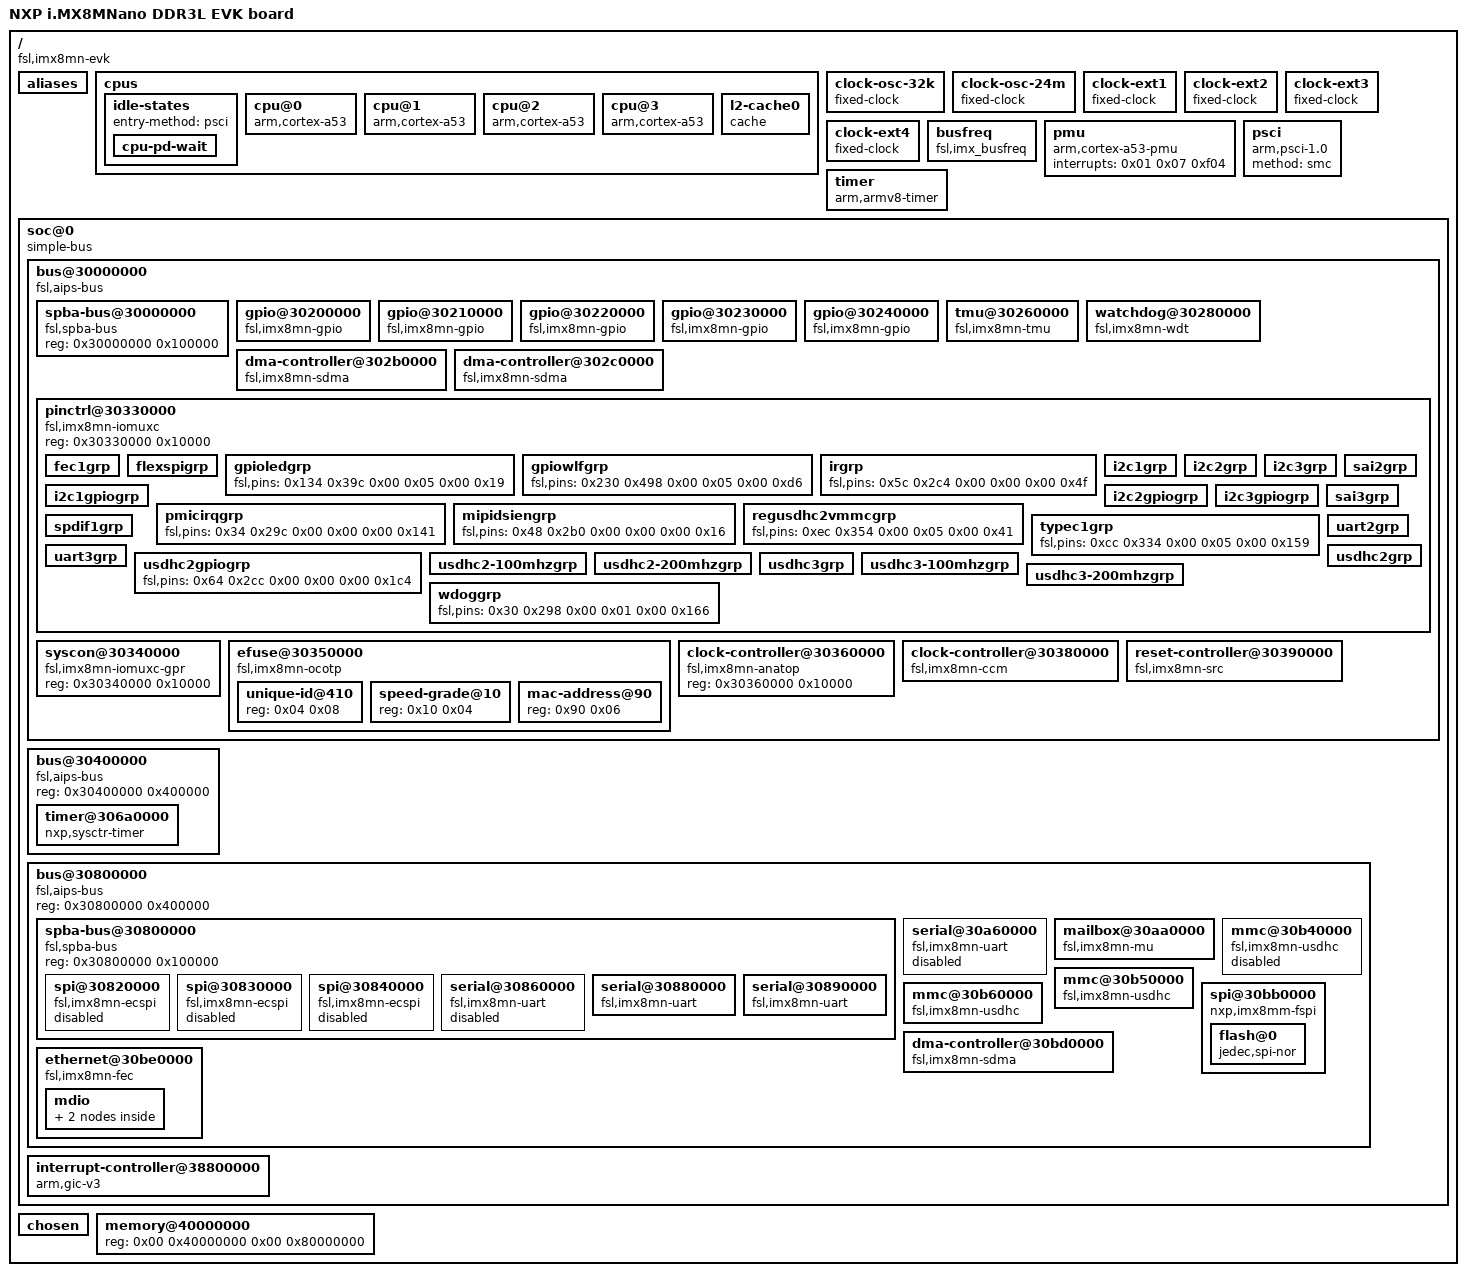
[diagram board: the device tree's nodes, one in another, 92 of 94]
/dts-v1/;

/ {
	interrupt-parent = <0x01>;
	#address-cells = <0x02>;
	#size-cells = <0x02>;
	model = "NXP i.MX8MNano DDR3L EVK board";
	compatible = "fsl,imx8mn-evk\0fsl,imx8mn";

	aliases {
		ethernet0 = "/soc@0/bus@30800000/ethernet@30be0000";
		gpio0 = "/soc@0/bus@30000000/gpio@30200000";
		gpio1 = "/soc@0/bus@30000000/gpio@30210000";
		gpio2 = "/soc@0/bus@30000000/gpio@30220000";
		gpio3 = "/soc@0/bus@30000000/gpio@30230000";
		gpio4 = "/soc@0/bus@30000000/gpio@30240000";
		mmc0 = "/soc@0/bus@30800000/mmc@30b40000";
		mmc1 = "/soc@0/bus@30800000/mmc@30b50000";
		mmc2 = "/soc@0/bus@30800000/mmc@30b60000";
		serial0 = "/soc@0/bus@30800000/spba-bus@30800000/serial@30860000";
		serial1 = "/soc@0/bus@30800000/spba-bus@30800000/serial@30890000";
		serial2 = "/soc@0/bus@30800000/spba-bus@30800000/serial@30880000";
		serial3 = "/soc@0/bus@30800000/serial@30a60000";
		spi0 = "/soc@0/bus@30800000/spi@30bb0000";
	};

	cpus {
		#address-cells = <0x01>;
		#size-cells = <0x00>;

		idle-states {
			entry-method = "psci";

			cpu-pd-wait {
				arm,psci-suspend-param = <0x10033>;
				local-timer-stop;
				entry-latency-us = <0x3e8>;
				exit-latency-us = <0x2bc>;
				min-residency-us = <0xa8c>;
				phandle = <0x06>;
			};
		};

		cpu@0 {
			device_type = "cpu";
			compatible = "arm,cortex-a53";
			reg = <0x00>;
			clock-latency = <0xee6c>;
			clocks = <0x02 0xbf>;
			enable-method = "psci";
			i-cache-size = <0x8000>;
			i-cache-line-size = <0x40>;
			i-cache-sets = <0x100>;
			d-cache-size = <0x8000>;
			d-cache-line-size = <0x40>;
			d-cache-sets = <0x80>;
			next-level-cache = <0x03>;
			operating-points-v2 = <0x04>;
			nvmem-cells = <0x05>;
			nvmem-cell-names = "speed_grade";
			cpu-idle-states = <0x06>;
			#cooling-cells = <0x02>;
			cpu-supply = <0x07>;
			phandle = <0x0a>;
		};

		cpu@1 {
			device_type = "cpu";
			compatible = "arm,cortex-a53";
			reg = <0x01>;
			clock-latency = <0xee6c>;
			clocks = <0x02 0xbf>;
			enable-method = "psci";
			i-cache-size = <0x8000>;
			i-cache-line-size = <0x40>;
			i-cache-sets = <0x100>;
			d-cache-size = <0x8000>;
			d-cache-line-size = <0x40>;
			d-cache-sets = <0x80>;
			next-level-cache = <0x03>;
			operating-points-v2 = <0x04>;
			cpu-idle-states = <0x06>;
			#cooling-cells = <0x02>;
			cpu-supply = <0x07>;
			phandle = <0x0b>;
		};

		cpu@2 {
			device_type = "cpu";
			compatible = "arm,cortex-a53";
			reg = <0x02>;
			clock-latency = <0xee6c>;
			clocks = <0x02 0xbf>;
			enable-method = "psci";
			i-cache-size = <0x8000>;
			i-cache-line-size = <0x40>;
			i-cache-sets = <0x100>;
			d-cache-size = <0x8000>;
			d-cache-line-size = <0x40>;
			d-cache-sets = <0x80>;
			next-level-cache = <0x03>;
			operating-points-v2 = <0x04>;
			cpu-idle-states = <0x06>;
			#cooling-cells = <0x02>;
			cpu-supply = <0x07>;
			phandle = <0x0c>;
		};

		cpu@3 {
			device_type = "cpu";
			compatible = "arm,cortex-a53";
			reg = <0x03>;
			clock-latency = <0xee6c>;
			clocks = <0x02 0xbf>;
			enable-method = "psci";
			i-cache-size = <0x8000>;
			i-cache-line-size = <0x40>;
			i-cache-sets = <0x100>;
			d-cache-size = <0x8000>;
			d-cache-line-size = <0x40>;
			d-cache-sets = <0x80>;
			next-level-cache = <0x03>;
			operating-points-v2 = <0x04>;
			cpu-idle-states = <0x06>;
			#cooling-cells = <0x02>;
			cpu-supply = <0x07>;
			phandle = <0x0d>;
		};

		l2-cache0 {
			compatible = "cache";
			cache-level = <0x02>;
			cache-size = <0x80000>;
			cache-line-size = <0x40>;
			cache-sets = <0x200>;
			phandle = <0x03>;
		};
	};

	clock-osc-32k {
		compatible = "fixed-clock";
		#clock-cells = <0x00>;
		clock-frequency = <0x8000>;
		clock-output-names = "osc_32k";
		u-boot,dm-spl;
		u-boot,dm-pre-reloc;
		phandle = <0x16>;
	};

	clock-osc-24m {
		compatible = "fixed-clock";
		#clock-cells = <0x00>;
		clock-frequency = <0x16e3600>;
		clock-output-names = "osc_24m";
		u-boot,dm-spl;
		u-boot,dm-pre-reloc;
		phandle = <0x17>;
	};

	clock-ext1 {
		compatible = "fixed-clock";
		#clock-cells = <0x00>;
		clock-frequency = <0x7ed6b40>;
		clock-output-names = "clk_ext1";
		u-boot,dm-spl;
		u-boot,dm-pre-reloc;
		phandle = <0x18>;
	};

	clock-ext2 {
		compatible = "fixed-clock";
		#clock-cells = <0x00>;
		clock-frequency = <0x7ed6b40>;
		clock-output-names = "clk_ext2";
		u-boot,dm-spl;
		u-boot,dm-pre-reloc;
		phandle = <0x19>;
	};

	clock-ext3 {
		compatible = "fixed-clock";
		#clock-cells = <0x00>;
		clock-frequency = <0x7ed6b40>;
		clock-output-names = "clk_ext3";
		u-boot,dm-spl;
		u-boot,dm-pre-reloc;
		phandle = <0x1a>;
	};

	clock-ext4 {
		compatible = "fixed-clock";
		#clock-cells = <0x00>;
		clock-frequency = <0x7ed6b40>;
		clock-output-names = "clk_ext4";
		u-boot,dm-spl;
		u-boot,dm-pre-reloc;
		phandle = <0x1b>;
	};

	busfreq {
		compatible = "fsl,imx_busfreq";
		clocks = <0x02 0x29 0x02 0x59 0x02 0x5a 0x02 0x5a 0x02 0x58 0x02 0x5b 0x02 0x30 0x02 0x32 0x02 0x3f 0x02 0x53 0x02 0x54 0x02 0x4b 0x02 0x02 0x02 0x38 0x02 0x15>;
		clock-names = "dram_pll\0dram_alt_src\0dram_apb_src\0dram_apb_pre_div\0dram_core\0dram_alt_root\0sys_pll1_40m\0sys_pll1_100m\0sys_pll2_333m\0noc_div\0ahb_div\0main_axi_src\0osc_24m\0sys_pll1_800m\0dram_pll_div";
	};

	pmu {
		compatible = "arm,cortex-a53-pmu";
		interrupts = <0x01 0x07 0xf04>;
	};

	psci {
		compatible = "arm,psci-1.0";
		method = "smc";
	};

	timer {
		compatible = "arm,armv8-timer";
		interrupts = <0x01 0x0d 0xf08 0x01 0x0e 0xf08 0x01 0x0b 0xf08 0x01 0x0a 0xf08>;
		clock-frequency = <0x7a1200>;
		arm,no-tick-in-suspend;
	};

	soc@0 {
		compatible = "simple-bus";
		#address-cells = <0x01>;
		#size-cells = <0x01>;
		ranges = <0x00 0x00 0x00 0x3e000000>;
		dma-ranges = <0x40000000 0x00 0x40000000 0xc0000000>;
		nvmem-cells = <0x0e>;
		nvmem-cell-names = "soc_unique_id";
		u-boot,dm-pre-reloc;
		u-boot,dm-spl;
		phandle = <0x5e>;

		bus@30000000 {
			compatible = "fsl,aips-bus\0simple-bus";
			reg = <0x30000000 0x400000>;
			#address-cells = <0x01>;
			#size-cells = <0x01>;
			ranges;
			u-boot,dm-spl;
			u-boot,dm-pre-reloc;
			phandle = <0x60>;

			spba-bus@30000000 {
				compatible = "fsl,spba-bus\0simple-bus";
				#address-cells = <0x01>;
				#size-cells = <0x01>;
				reg = <0x30000000 0x100000>;
				ranges;
				phandle = <0x61>;

			};

			gpio@30200000 {
				compatible = "fsl,imx8mn-gpio\0fsl,imx35-gpio";
				reg = <0x30200000 0x10000>;
				interrupts = <0x00 0x40 0x04 0x00 0x41 0x04>;
				clocks = <0x02 0x8c>;
				gpio-controller;
				#gpio-cells = <0x02>;
				interrupt-controller;
				#interrupt-cells = <0x02>;
				gpio-ranges = <0x13 0x00 0x0a 0x1e>;
				u-boot,dm-spl;
				phandle = <0x24>;
			};

			gpio@30210000 {
				compatible = "fsl,imx8mn-gpio\0fsl,imx35-gpio";
				reg = <0x30210000 0x10000>;
				interrupts = <0x00 0x42 0x04 0x00 0x43 0x04>;
				clocks = <0x02 0x8d>;
				gpio-controller;
				#gpio-cells = <0x02>;
				interrupt-controller;
				#interrupt-cells = <0x02>;
				gpio-ranges = <0x13 0x00 0x28 0x15>;
				u-boot,dm-spl;
				phandle = <0x29>;
			};

			gpio@30220000 {
				compatible = "fsl,imx8mn-gpio\0fsl,imx35-gpio";
				reg = <0x30220000 0x10000>;
				interrupts = <0x00 0x44 0x04 0x00 0x45 0x04>;
				clocks = <0x02 0x8e>;
				gpio-controller;
				#gpio-cells = <0x02>;
				interrupt-controller;
				#interrupt-cells = <0x02>;
				gpio-ranges = <0x13 0x00 0x3d 0x1a>;
				u-boot,dm-spl;
				phandle = <0x4d>;
			};

			gpio@30230000 {
				compatible = "fsl,imx8mn-gpio\0fsl,imx35-gpio";
				reg = <0x30230000 0x10000>;
				interrupts = <0x00 0x46 0x04 0x00 0x47 0x04>;
				clocks = <0x02 0x8f>;
				gpio-controller;
				#gpio-cells = <0x02>;
				interrupt-controller;
				#interrupt-cells = <0x02>;
				gpio-ranges = <0x13 0x15 0x6c 0x0b>;
				u-boot,dm-spl;
				phandle = <0x3a>;
			};

			gpio@30240000 {
				compatible = "fsl,imx8mn-gpio\0fsl,imx35-gpio";
				reg = <0x30240000 0x10000>;
				interrupts = <0x00 0x48 0x04 0x00 0x49 0x04>;
				clocks = <0x02 0x90>;
				gpio-controller;
				#gpio-cells = <0x02>;
				interrupt-controller;
				#interrupt-cells = <0x02>;
				gpio-ranges = <0x13 0x00 0x77 0x1e>;
				u-boot,dm-spl;
				phandle = <0x22>;
			};

			tmu@30260000 {
				compatible = "fsl,imx8mn-tmu\0fsl,imx8mm-tmu";
				reg = <0x30260000 0x10000>;
				clocks = <0x02 0xbe>;
				#thermal-sensor-cells = <0x00>;
				u-boot,dm-pre-reloc;
				phandle = <0x08>;
			};

			watchdog@30280000 {
				compatible = "fsl,imx8mn-wdt\0fsl,imx21-wdt";
				reg = <0x30280000 0x10000>;
				interrupts = <0x00 0x4e 0x04>;
				clocks = <0x02 0xb0>;
				status = "okay";
				pinctrl-names = "default";
				pinctrl-0 = <0x14>;
				fsl,ext-reset-output;
				u-boot,dm-spl;
				phandle = <0x5a>;
			};


			dma-controller@302b0000 {
				compatible = "fsl,imx8mn-sdma\0fsl,imx8mq-sdma";
				reg = <0x302b0000 0x10000>;
				interrupts = <0x00 0x22 0x04>;
				clocks = <0x02 0xbd 0x02 0xbd>;
				clock-names = "ipg\0ahb";
				#dma-cells = <0x03>;
				fsl,sdma-ram-script-name = "imx/sdma/sdma-imx7d.bin";
				phandle = <0x68>;
			};

			dma-controller@302c0000 {
				compatible = "fsl,imx8mn-sdma\0fsl,imx8mq-sdma";
				reg = <0x302c0000 0x10000>;
				interrupts = <0x00 0x67 0x04>;
				clocks = <0x02 0xa8 0x02 0xa8>;
				clock-names = "ipg\0ahb";
				#dma-cells = <0x03>;
				fsl,sdma-ram-script-name = "imx/sdma/sdma-imx7d.bin";
				phandle = <0x0f>;
			};

			pinctrl@30330000 {
				compatible = "fsl,imx8mn-iomuxc";
				reg = <0x30330000 0x10000>;
				u-boot,dm-spl;
				phandle = <0x13>;

				fec1grp {
					fsl,pins = <0x68 0x2d0 0x00 0x00 0x00 0x03 0x6c 0x2d4 0x4c0 0x00 0x01 0x03 0x70 0x2d8 0x00 0x00 0x00 0x1f 0x74 0x2dc 0x00 0x00 0x00 0x1f 0x78 0x2e0 0x00 0x00 0x00 0x1f 0x7c 0x2e4 0x00 0x00 0x00 0x1f 0x9c 0x304 0x00 0x00 0x00 0x91 0x98 0x300 0x00 0x00 0x00 0x91 0x94 0x2fc 0x554 0x00 0x00 0x91 0x90 0x2f8 0x57c 0x00 0x00 0x91 0x84 0x2ec 0x00 0x00 0x00 0x1f 0x8c 0x2f4 0x00 0x00 0x00 0x91 0x88 0x2f0 0x574 0x00 0x00 0x91 0x80 0x2e8 0x00 0x00 0x00 0x1f 0x1b4 0x41c 0x00 0x05 0x00 0x19>;
					phandle = <0x38>;
				};

				flexspigrp {
					fsl,pins = <0xf4 0x35c 0x00 0x01 0x00 0x1c2 0xf8 0x360 0x00 0x01 0x00 0x82 0x10c 0x374 0x00 0x01 0x00 0x82 0x110 0x378 0x00 0x01 0x00 0x82 0x114 0x37c 0x00 0x01 0x00 0x82 0x118 0x380 0x00 0x01 0x00 0x82>;
					phandle = <0x35>;
				};

				gpioledgrp {
					fsl,pins = <0x134 0x39c 0x00 0x05 0x00 0x19>;
					phandle = <0x4c>;
				};

				gpiowlfgrp {
					fsl,pins = <0x230 0x498 0x00 0x05 0x00 0xd6>;
					phandle = <0x50>;
				};

				irgrp {
					fsl,pins = <0x5c 0x2c4 0x00 0x00 0x00 0x4f>;
					phandle = <0x4f>;
				};

				i2c1grp {
					fsl,pins = <0x214 0x47c 0x55c 0x00 0x00 0x400001c3 0x218 0x480 0x56c 0x00 0x00 0x400001c3>;
					u-boot,dm-spl;
					phandle = <0x20>;
				};

				i2c2grp {
					fsl,pins = <0x21c 0x484 0x5d0 0x00 0x00 0x400001c3 0x220 0x488 0x560 0x00 0x00 0x400001c3>;
					phandle = <0x25>;
				};

				i2c3grp {
					fsl,pins = <0x224 0x48c 0x588 0x00 0x00 0x400001c3 0x228 0x490 0x5bc 0x00 0x00 0x400001c3>;
					phandle = <0x2b>;
				};

				i2c1gpiogrp {
					fsl,pins = <0x214 0x47c 0x00 0x05 0x00 0x1c3 0x218 0x480 0x00 0x05 0x00 0x1c3>;
					u-boot,dm-spl;
					phandle = <0x21>;
				};

				i2c2gpiogrp {
					fsl,pins = <0x21c 0x484 0x00 0x05 0x00 0x1c3 0x220 0x488 0x00 0x05 0x00 0x1c3>;
					phandle = <0x26>;
				};

				i2c3gpiogrp {
					fsl,pins = <0x224 0x48c 0x00 0x05 0x00 0x1c3 0x228 0x490 0x00 0x05 0x00 0x1c3>;
					phandle = <0x2c>;
				};

				pmicirqgrp {
					fsl,pins = <0x34 0x29c 0x00 0x00 0x00 0x141>;
					u-boot,dm-spl;
					phandle = <0x23>;
				};

				mipidsiengrp {
					fsl,pins = <0x48 0x2b0 0x00 0x00 0x00 0x16>;
					phandle = <0x58>;
				};

				regusdhc2vmmcgrp {
					fsl,pins = <0xec 0x354 0x00 0x05 0x00 0x41>;
					u-boot,dm-spl;
					phandle = <0x4e>;
				};

				sai2grp {
					fsl,pins = <0x1c0 0x428 0x00 0x00 0x00 0xd6 0x1bc 0x424 0x00 0x00 0x00 0xd6 0x1c4 0x42c 0x00 0x00 0x00 0xd6 0x1b8 0x420 0x00 0x00 0x00 0xd6>;
					phandle = <0x10>;
				};

				sai3grp {
					fsl,pins = <0x1d8 0x440 0x00 0x00 0x00 0xd6 0x1dc 0x444 0x00 0x00 0x00 0xd6 0x1e4 0x44c 0x5c0 0x00 0x00 0xd6 0x1e0 0x448 0x00 0x00 0x00 0xd6>;
					phandle = <0x11>;
				};

				spdif1grp {
					fsl,pins = <0x1e8 0x450 0x00 0x00 0x00 0xd6 0x1ec 0x454 0x5cc 0x00 0x00 0xd6>;
					phandle = <0x12>;
				};

				typec1grp {
					fsl,pins = <0xcc 0x334 0x00 0x05 0x00 0x159>;
					phandle = <0x28>;
				};

				uart2grp {
					fsl,pins = <0x23c 0x4a4 0x4fc 0x00 0x00 0x140 0x240 0x4a8 0x00 0x00 0x00 0x140>;
					u-boot,dm-spl;
					phandle = <0x1f>;
				};

				uart3grp {
					fsl,pins = <0x1f4 0x45c 0x504 0x01 0x00 0x140 0x1f8 0x460 0x00 0x01 0x00 0x140 0x200 0x468 0x500 0x01 0x01 0x140 0x1fc 0x464 0x00 0x01 0x00 0x140>;
					phandle = <0x1e>;
				};

				usdhc2gpiogrp {
					fsl,pins = <0x64 0x2cc 0x00 0x00 0x00 0x1c4>;
					u-boot,dm-spl;
					phandle = <0x2e>;
				};

				usdhc2grp {
					fsl,pins = <0xd4 0x33c 0x00 0x00 0x00 0x190 0xd8 0x340 0x00 0x00 0x00 0x1d0 0xdc 0x344 0x00 0x00 0x00 0x1d0 0xe0 0x348 0x00 0x00 0x00 0x1d0 0xe4 0x34c 0x00 0x00 0x00 0x1d0 0xe8 0x350 0x00 0x00 0x00 0x1d0 0x38 0x2a0 0x00 0x01 0x00 0x1d0>;
					u-boot,dm-spl;
					phandle = <0x2d>;
				};

				usdhc2-100mhzgrp {
					fsl,pins = <0xd4 0x33c 0x00 0x00 0x00 0x194 0xd8 0x340 0x00 0x00 0x00 0x1d4 0xdc 0x344 0x00 0x00 0x00 0x1d4 0xe0 0x348 0x00 0x00 0x00 0x1d4 0xe4 0x34c 0x00 0x00 0x00 0x1d4 0xe8 0x350 0x00 0x00 0x00 0x1d4 0x38 0x2a0 0x00 0x01 0x00 0x1d0>;
					phandle = <0x2f>;
				};

				usdhc2-200mhzgrp {
					fsl,pins = <0xd4 0x33c 0x00 0x00 0x00 0x196 0xd8 0x340 0x00 0x00 0x00 0x1d6 0xdc 0x344 0x00 0x00 0x00 0x1d6 0xe0 0x348 0x00 0x00 0x00 0x1d6 0xe4 0x34c 0x00 0x00 0x00 0x1d6 0xe8 0x350 0x00 0x00 0x00 0x1d6 0x38 0x2a0 0x00 0x01 0x00 0x1d0>;
					phandle = <0x30>;
				};

				usdhc3grp {
					fsl,pins = <0x138 0x3a0 0x5a0 0x02 0x00 0x40000190 0x13c 0x3a4 0x5dc 0x02 0x00 0x1d0 0x11c 0x384 0x5b4 0x02 0x00 0x1d0 0x120 0x388 0x5b0 0x02 0x00 0x1d0 0x124 0x38c 0x5e4 0x02 0x00 0x1d0 0x128 0x390 0x5e0 0x02 0x00 0x1d0 0x130 0x398 0x558 0x02 0x00 0x1d0 0x100 0x368 0x550 0x02 0x00 0x1d0 0x104 0x36c 0x584 0x02 0x00 0x1d0 0x108 0x370 0x54c 0x02 0x00 0x1d0 0xfc 0x364 0x59c 0x02 0x00 0x190>;
					u-boot,dm-spl;
					phandle = <0x32>;
				};

				usdhc3-100mhzgrp {
					fsl,pins = <0x138 0x3a0 0x5a0 0x02 0x00 0x40000194 0x13c 0x3a4 0x5dc 0x02 0x00 0x1d4 0x11c 0x384 0x5b4 0x02 0x00 0x1d4 0x120 0x388 0x5b0 0x02 0x00 0x1d4 0x124 0x38c 0x5e4 0x02 0x00 0x1d4 0x128 0x390 0x5e0 0x02 0x00 0x1d4 0x130 0x398 0x558 0x02 0x00 0x1d4 0x100 0x368 0x550 0x02 0x00 0x1d4 0x104 0x36c 0x584 0x02 0x00 0x1d4 0x108 0x370 0x54c 0x02 0x00 0x1d4 0xfc 0x364 0x59c 0x02 0x00 0x194>;
					phandle = <0x33>;
				};

				usdhc3-200mhzgrp {
					fsl,pins = <0x138 0x3a0 0x5a0 0x02 0x00 0x40000196 0x13c 0x3a4 0x5dc 0x02 0x00 0x1d6 0x11c 0x384 0x5b4 0x02 0x00 0x1d6 0x120 0x388 0x5b0 0x02 0x00 0x1d6 0x124 0x38c 0x5e4 0x02 0x00 0x1d6 0x128 0x390 0x5e0 0x02 0x00 0x1d6 0x130 0x398 0x558 0x02 0x00 0x1d6 0x100 0x368 0x550 0x02 0x00 0x1d6 0x104 0x36c 0x584 0x02 0x00 0x1d6 0x108 0x370 0x54c 0x02 0x00 0x1d6 0xfc 0x364 0x59c 0x02 0x00 0x196>;
					phandle = <0x34>;
				};

				wdoggrp {
					fsl,pins = <0x30 0x298 0x00 0x01 0x00 0x166>;
					u-boot,dm-spl;
					phandle = <0x14>;
				};
			};

			syscon@30340000 {
				compatible = "fsl,imx8mn-iomuxc-gpr\0syscon";
				reg = <0x30340000 0x10000>;
				phandle = <0x37>;
			};

			efuse@30350000 {
				compatible = "fsl,imx8mn-ocotp\0fsl,imx8mm-ocotp\0syscon";
				reg = <0x30350000 0x10000>;
				clocks = <0x02 0x96>;
				#address-cells = <0x01>;
				#size-cells = <0x01>;
				phandle = <0x69>;

				unique-id@410 {
					reg = <0x04 0x08>;
					phandle = <0x0e>;
				};

				speed-grade@10 {
					reg = <0x10 0x04>;
					phandle = <0x05>;
				};

				mac-address@90 {
					reg = <0x90 0x06>;
					phandle = <0x36>;
				};
			};

			clock-controller@30360000 {
				compatible = "fsl,imx8mn-anatop\0fsl,imx8mm-anatop";
				reg = <0x30360000 0x10000>;
				#clock-cells = <0x01>;
				phandle = <0x6a>;
			};

			clock-controller@30380000 {
				compatible = "fsl,imx8mn-ccm";
				reg = <0x30380000 0x10000>;
				#clock-cells = <0x01>;
				clocks = <0x16 0x17 0x18 0x19 0x1a 0x1b>;
				clock-names = "osc_32k\0osc_24m\0clk_ext1\0clk_ext2\0clk_ext3\0clk_ext4";
				u-boot,dm-spl;
				u-boot,dm-pre-reloc;
				phandle = <0x02>;
			};

			reset-controller@30390000 {
				compatible = "fsl,imx8mn-src\0fsl,imx8mq-src\0syscon";
				reg = <0x30390000 0x10000>;
				interrupts = <0x00 0x59 0x04>;
				#reset-cells = <0x01>;
				phandle = <0x6f>;
			};

		};

		bus@30400000 {
			compatible = "fsl,aips-bus\0simple-bus";
			reg = <0x30400000 0x400000>;
			#address-cells = <0x01>;
			#size-cells = <0x01>;
			ranges;
			u-boot,dm-spl;
			phandle = <0x71>;

			timer@306a0000 {
				compatible = "nxp,sysctr-timer";
				reg = <0x306a0000 0x20000>;
				interrupts = <0x00 0x2f 0x04>;
				clocks = <0x17>;
				clock-names = "per";
				phandle = <0x76>;
			};
		};

		bus@30800000 {
			compatible = "fsl,aips-bus\0simple-bus";
			reg = <0x30800000 0x400000>;
			#address-cells = <0x01>;
			#size-cells = <0x01>;
			ranges;
			u-boot,dm-spl;
			phandle = <0x77>;

			spba-bus@30800000 {
				compatible = "fsl,spba-bus\0simple-bus";
				#address-cells = <0x01>;
				#size-cells = <0x01>;
				reg = <0x30800000 0x100000>;
				ranges;
				u-boot,dm-spl;
				phandle = <0x78>;

				spi@30820000 {
					compatible = "fsl,imx8mn-ecspi\0fsl,imx51-ecspi";
					#address-cells = <0x01>;
					#size-cells = <0x00>;
					reg = <0x30820000 0x10000>;
					interrupts = <0x00 0x1f 0x04>;
					clocks = <0x02 0x88 0x02 0x88>;
					clock-names = "ipg\0per";
					dmas = <0x1d 0x00 0x07 0x01 0x1d 0x01 0x07 0x02>;
					dma-names = "rx\0tx";
					status = "disabled";
					phandle = <0x79>;
				};

				spi@30830000 {
					compatible = "fsl,imx8mn-ecspi\0fsl,imx51-ecspi";
					#address-cells = <0x01>;
					#size-cells = <0x00>;
					reg = <0x30830000 0x10000>;
					interrupts = <0x00 0x20 0x04>;
					clocks = <0x02 0x89 0x02 0x89>;
					clock-names = "ipg\0per";
					dmas = <0x1d 0x02 0x07 0x01 0x1d 0x03 0x07 0x02>;
					dma-names = "rx\0tx";
					status = "disabled";
					phandle = <0x7a>;
				};

				spi@30840000 {
					compatible = "fsl,imx8mn-ecspi\0fsl,imx51-ecspi";
					#address-cells = <0x01>;
					#size-cells = <0x00>;
					reg = <0x30840000 0x10000>;
					interrupts = <0x00 0x21 0x04>;
					clocks = <0x02 0x8a 0x02 0x8a>;
					clock-names = "ipg\0per";
					dmas = <0x1d 0x04 0x07 0x01 0x1d 0x05 0x07 0x02>;
					dma-names = "rx\0tx";
					status = "disabled";
					phandle = <0x7b>;
				};

				serial@30860000 {
					compatible = "fsl,imx8mn-uart\0fsl,imx6q-uart";
					reg = <0x30860000 0x10000>;
					interrupts = <0x00 0x1a 0x04>;
					clocks = <0x02 0xa9 0x02 0xa9>;
					clock-names = "ipg\0per";
					dmas = <0x1d 0x16 0x04 0x00 0x1d 0x17 0x04 0x00>;
					dma-names = "rx\0tx";
					status = "disabled";
					phandle = <0x7c>;
				};

				serial@30880000 {
					compatible = "fsl,imx8mn-uart\0fsl,imx6q-uart";
					reg = <0x30880000 0x10000>;
					interrupts = <0x00 0x1c 0x04>;
					clocks = <0x02 0xab 0x02 0xab>;
					clock-names = "ipg\0per";
					dmas = <0x1d 0x1a 0x04 0x00 0x1d 0x1b 0x04 0x00>;
					dma-names = "rx\0tx";
					status = "okay";
					pinctrl-names = "default";
					pinctrl-0 = <0x1e>;
					assigned-clocks = <0x02 0x6f>;
					assigned-clock-parents = <0x02 0x31>;
					uart-has-rtscts;
					phandle = <0x7d>;
				};

				serial@30890000 {
					compatible = "fsl,imx8mn-uart\0fsl,imx6q-uart";
					reg = <0x30890000 0x10000>;
					interrupts = <0x00 0x1b 0x04>;
					clocks = <0x02 0xaa 0x02 0xaa>;
					clock-names = "ipg\0per";
					status = "okay";
					pinctrl-names = "default";
					pinctrl-0 = <0x1f>;
					u-boot,dm-spl;
					phandle = <0x7e>;
				};
			};

			serial@30a60000 {
				compatible = "fsl,imx8mn-uart\0fsl,imx6q-uart";
				reg = <0x30a60000 0x10000>;
				interrupts = <0x00 0x1d 0x04>;
				clocks = <0x02 0xac 0x02 0xac>;
				clock-names = "ipg\0per";
				dmas = <0x1d 0x1c 0x04 0x00 0x1d 0x1d 0x04 0x00>;
				dma-names = "rx\0tx";
				status = "disabled";
				phandle = <0x94>;
			};

			mailbox@30aa0000 {
				compatible = "fsl,imx8mn-mu\0fsl,imx6sx-mu";
				reg = <0x30aa0000 0x10000>;
				interrupts = <0x00 0x58 0x04>;
				clocks = <0x02 0x95>;
				#mbox-cells = <0x02>;
				phandle = <0x95>;
			};

			mmc@30b40000 {
				compatible = "fsl,imx8mn-usdhc\0fsl,imx8mm-usdhc\0fsl,imx7d-usdhc";
				reg = <0x30b40000 0x10000>;
				interrupts = <0x00 0x16 0x04>;
				clocks = <0x02 0x56 0x02 0x4d 0x02 0xae>;
				clock-names = "ipg\0ahb\0per";
				fsl,tuning-start-tap = <0x14>;
				fsl,tuning-step = <0x02>;
				bus-width = <0x04>;
				status = "disabled";
				u-boot,dm-spl;
				assigned-clocks = <0x02 0x67>;
				assigned-clock-rates = <0x17d78400>;
				assigned-clock-parents = <0x02 0x37>;
				phandle = <0x96>;
			};

			mmc@30b50000 {
				compatible = "fsl,imx8mn-usdhc\0fsl,imx8mm-usdhc\0fsl,imx7d-usdhc";
				reg = <0x30b50000 0x10000>;
				interrupts = <0x00 0x17 0x04>;
				clocks = <0x02 0x56 0x02 0x4d 0x02 0xaf>;
				clock-names = "ipg\0ahb\0per";
				fsl,tuning-start-tap = <0x14>;
				fsl,tuning-step = <0x02>;
				bus-width = <0x04>;
				status = "okay";
				assigned-clocks = <0x02 0x68>;
				assigned-clock-rates = <0x17d78400>;
				pinctrl-names = "default\0state_100mhz\0state_200mhz";
				pinctrl-0 = <0x2d 0x2e>;
				pinctrl-1 = <0x2f 0x2e>;
				pinctrl-2 = <0x30 0x2e>;
				cd-gpios = <0x24 0x0f 0x01>;
				vmmc-supply = <0x31>;
				u-boot,dm-spl;
				sd-uhs-sdr104;
				sd-uhs-ddr50;
				assigned-clock-parents = <0x02 0x37>;
				phandle = <0x97>;
			};

			mmc@30b60000 {
				compatible = "fsl,imx8mn-usdhc\0fsl,imx8mm-usdhc\0fsl,imx7d-usdhc";
				reg = <0x30b60000 0x10000>;
				interrupts = <0x00 0x18 0x04>;
				clocks = <0x02 0x56 0x02 0x4d 0x02 0xbc>;
				clock-names = "ipg\0ahb\0per";
				fsl,tuning-start-tap = <0x14>;
				fsl,tuning-step = <0x02>;
				bus-width = <0x08>;
				status = "okay";
				assigned-clocks = <0x02 0x80>;
				assigned-clock-rates = <0x17d78400>;
				pinctrl-names = "default\0state_100mhz\0state_200mhz";
				pinctrl-0 = <0x32>;
				pinctrl-1 = <0x33>;
				pinctrl-2 = <0x34>;
				non-removable;
				u-boot,dm-spl;
				mmc-hs400-1_8v;
				mmc-hs400-enhanced-strobe;
				assigned-clock-parents = <0x02 0x37>;
				phandle = <0x98>;
			};

			spi@30bb0000 {
				#address-cells = <0x01>;
				#size-cells = <0x00>;
				compatible = "nxp,imx8mm-fspi";
				reg = <0x30bb0000 0x10000 0x8000000 0x10000000>;
				reg-names = "fspi_base\0fspi_mmap";
				interrupts = <0x00 0x6b 0x04>;
				clocks = <0x02 0x9b 0x02 0x9b>;
				clock-names = "fspi_en\0fspi";
				assigned-clock-rates = <0x4c4b400>;
				assigned-clocks = <0x02 0x66>;
				assigned-clock-parents = <0x02 0x37>;
				status = "okay";
				pinctrl-names = "default";
				pinctrl-0 = <0x35>;
				phandle = <0x99>;

				flash@0 {
					compatible = "jedec,spi-nor";
					reg = <0x00>;
					#address-cells = <0x01>;
					#size-cells = <0x01>;
					spi-max-frequency = <0x9e4f580>;
					spi-tx-bus-width = <0x01>;
					spi-rx-bus-width = <0x04>;
					phandle = <0x9a>;
				};
			};

			dma-controller@30bd0000 {
				compatible = "fsl,imx8mn-sdma\0fsl,imx8mq-sdma";
				reg = <0x30bd0000 0x10000>;
				interrupts = <0x00 0x02 0x04>;
				clocks = <0x02 0xa7 0x02 0x54>;
				clock-names = "ipg\0ahb";
				#dma-cells = <0x03>;
				fsl,sdma-ram-script-name = "imx/sdma/sdma-imx7d.bin";
				phandle = <0x1d>;
			};

			ethernet@30be0000 {
				compatible = "fsl,imx8mn-fec\0fsl,imx8mq-fec\0fsl,imx6sx-fec";
				reg = <0x30be0000 0x10000>;
				interrupts = <0x00 0x76 0x04 0x00 0x77 0x04 0x00 0x78 0x04 0x00 0x79 0x04>;
				clocks = <0x02 0x8b 0x02 0x8b 0x02 0x63 0x02 0x62 0x02 0x64>;
				clock-names = "ipg\0ahb\0ptp\0enet_clk_ref\0enet_out";
				assigned-clocks = <0x02 0x4c 0x02 0x63 0x02 0x62 0x02 0x64>;
				assigned-clock-parents = <0x02 0x36 0x02 0x3a 0x02 0x3b 0x02 0x39>;
				assigned-clock-rates = <0x00 0x5f5e100 0x7735940 0x00>;
				fsl,num-tx-queues = <0x03>;
				fsl,num-rx-queues = <0x03>;
				nvmem-cells = <0x36>;
				nvmem-cell-names = "mac-address";
				fsl,stop-mode = <0x37 0x10 0x03>;
				status = "okay";
				pinctrl-names = "default";
				pinctrl-0 = <0x38>;
				phy-mode = "rgmii-id";
				phy-handle = <0x39>;
				fsl,magic-packet;
				phy-reset-gpios = <0x3a 0x16 0x01>;
				phy-reset-duration = <0x0f>;
				phy-reset-post-delay = <0x64>;
				phandle = <0x9b>;

				mdio {
					#address-cells = <0x01>;
					#size-cells = <0x00>;

					ethernet-phy@0 {
						compatible = "ethernet-phy-ieee802.3-c22";
						reg = <0x00>;
						reset-gpios = <0x3a 0x16 0x01>;
						reset-assert-us = <0x3a98>;
						reset-deassert-us = <0x186a0>;
						qca,disable-smarteee;
						vddio-supply = <0x3b>;
						phandle = <0x39>;

						vddio-regulator {
							regulator-min-microvolt = <0x1b7740>;
							regulator-max-microvolt = <0x1b7740>;
							regulator-name = "VDDIO";
							phandle = <0x3b>;
						};
					};
				};
			};
		};

		interrupt-controller@38800000 {
			compatible = "arm,gic-v3";
			reg = <0x38800000 0x10000 0x38880000 0xc0000>;
			#interrupt-cells = <0x03>;
			interrupt-controller;
			interrupts = <0x01 0x09 0x04>;
			phandle = <0x01>;
		};
	};


	chosen {
		bootargs = "console=ttymxc1,115200 earlycon=ec_imx6q,0x30890000,115200";
		stdout-path = "/soc@0/bus@30800000/spba-bus@30800000/serial@30890000";
	};

	memory@40000000 {
		device_type = "memory";
		reg = <0x00 0x40000000 0x00 0x80000000>;
	};

};
